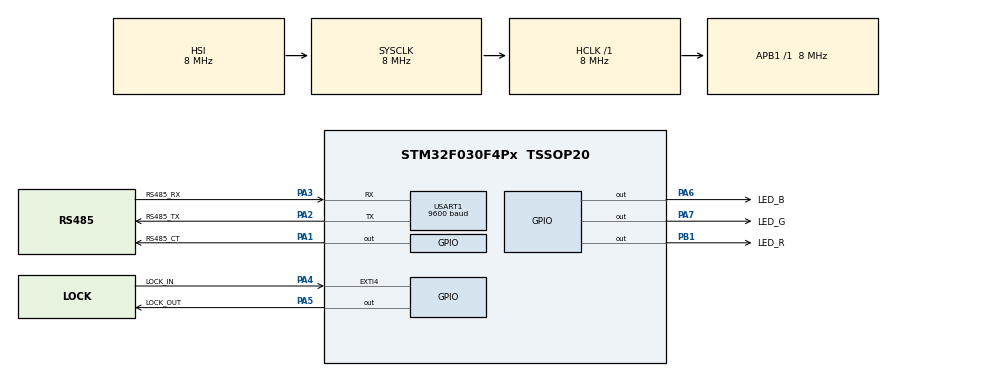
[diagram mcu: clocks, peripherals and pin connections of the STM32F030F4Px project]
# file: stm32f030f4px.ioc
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Dma.Request0=USART1_RX
Dma.Request1=USART1_TX
Dma.USART1_RX.0.Direction=DMA_PERIPH_TO_MEMORY
Dma.USART1_RX.0.Instance=DMA1_Channel3
Dma.USART1_RX.0.MemDataAlignment=DMA_MDATAALIGN_BYTE
Dma.USART1_RX.0.MemInc=DMA_MINC_ENABLE
Dma.USART1_RX.0.Mode=DMA_CIRCULAR
Dma.USART1_RX.0.PeriphDataAlignment=DMA_PDATAALIGN_BYTE
Dma.USART1_RX.0.PeriphInc=DMA_PINC_DISABLE
Dma.USART1_RX.0.Priority=DMA_PRIORITY_LOW
Dma.USART1_TX.1.Direction=DMA_MEMORY_TO_PERIPH
Dma.USART1_TX.1.Instance=DMA1_Channel2
Dma.USART1_TX.1.MemDataAlignment=DMA_MDATAALIGN_BYTE
Dma.USART1_TX.1.MemInc=DMA_MINC_ENABLE
Dma.USART1_TX.1.Mode=DMA_NORMAL
Dma.USART1_TX.1.PeriphDataAlignment=DMA_PDATAALIGN_BYTE
Dma.USART1_TX.1.PeriphInc=DMA_PINC_DISABLE
Dma.USART1_TX.1.Priority=DMA_PRIORITY_LOW
Mcu.Family=STM32F0
Mcu.Name=STM32F030F4Px
Mcu.Package=TSSOP20
NVIC.DMA1_Channel2_3_IRQn=true\:0\:0\:false\:false\:true\:false\:true\:true
NVIC.EXTI4_15_IRQn=true\:0\:0\:false\:false\:true\:true\:true\:true
NVIC.USART1_IRQn=true\:0\:0\:false\:false\:true\:true\:true\:true
PA1.GPIO_Label=RS485_CT
PA1.Signal=GPIO_Output
PA13.Mode=Serial_Wire
PA13.Signal=SYS_SWDIO
PA14.Mode=Serial_Wire
PA14.Signal=SYS_SWCLK
PA2.GPIO_Label=RS485_TX
PA2.Mode=Asynchronous
PA2.Signal=USART1_TX
PA3.GPIO_Label=RS485_RX
PA3.Mode=Asynchronous
PA3.Signal=USART1_RX
PA4.GPIO_Label=LOCK_IN
PA4.GPIO_ModeDefaultEXTI=GPIO_MODE_IT_RISING_FALLING
PA4.Signal=GPXTI4
PA5.GPIO_Label=LOCK_OUT
PA5.Signal=GPIO_Output
PA6.GPIO_Label=LED_B
PA6.Signal=GPIO_Output
PA7.GPIO_Label=LED_G
PA7.Signal=GPIO_Output
PB1.GPIO_Label=LED_R
PB1.Signal=GPIO_Output
PF0-OSC_IN.Mode=HSE-External-Oscillator
PF0-OSC_IN.Signal=RCC_OSC_IN
PF1-OSC_OUT.Mode=HSE-External-Oscillator
PF1-OSC_OUT.Signal=RCC_OSC_OUT
ProjectManager.HeapSize=0x200
ProjectManager.StackSize=0x400
ProjectManager.TargetToolchain=STM32CubeIDE
RCC.AHBFreq_Value=8000000
RCC.APB1Freq_Value=8000000
RCC.APB1TimFreq_Value=8000000
RCC.HCLKFreq_Value=8000000
RCC.PLLMUL=RCC_PLL_MUL6
RCC.PLLSourceVirtual=RCC_PLLSOURCE_HSE
RCC.SYSCLKFreq_VALUE=8000000
USART1.BaudRate=9600
USART1.VirtualMode-Asynchronous=VM_ASYNC
board=custom

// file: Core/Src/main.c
/* USER CODE BEGIN Header */
/**
  ******************************************************************************
  * @file           : main.c
  * @brief          : Main program body
  ******************************************************************************
  * @attention
  *
  * Copyright (c) 2026 STMicroelectronics.
  * All rights reserved.
  *
  * This software is licensed under terms that can be found in the LICENSE file
  * in the root directory of this software component.
  * If no LICENSE file comes with this software, it is provided AS-IS.
  *
  ******************************************************************************
  */
/* USER CODE END Header */
#include "main.h"
#include "dma.h"
#include "usart.h"
#include "gpio.h"

/* USER CODE BEGIN Includes */
#include "drv_mcu.h"
#include "app_doorlock.h"
/* USER CODE END Includes */

void SystemClock_Config(void);

int main(void)
{

  /* MCU Configuration--------------------------------------------------------*/

  /* Reset of all peripherals, Initializes the Flash interface and the Systick. */
  HAL_Init();

  /* Configure the system clock */
  SystemClock_Config();

  /* Initialize all configured peripherals */
  MX_GPIO_Init();
  MX_DMA_Init();
  MX_USART1_UART_Init();
  /* USER CODE BEGIN 2 */

  // 1. Init Drivers
  Drv_Init(&huart1);
  __HAL_UART_ENABLE_IT(&huart1, UART_IT_IDLE); // Interrupt Idle tetap dibutuhkan

  // 2. Init Application
  App_Init();

  /* USER CODE END 2 */

  /* Infinite loop */
  /* USER CODE BEGIN WHILE */
  while (1)
  {
	  // 3. Process Application Logic
	  App_Process();
    /* USER CODE END WHILE */

  }
}

void SystemClock_Config(void)
{
  RCC_OscInitTypeDef RCC_OscInitStruct = {0};
  RCC_ClkInitTypeDef RCC_ClkInitStruct = {0};
  RCC_PeriphCLKInitTypeDef PeriphClkInit = {0};

  /** Initializes the RCC Oscillators according to the specified parameters
  * in the RCC_OscInitTypeDef structure.
  */
  RCC_OscInitStruct.OscillatorType = RCC_OSCILLATORTYPE_HSI;
  RCC_OscInitStruct.HSIState = RCC_HSI_ON;
  RCC_OscInitStruct.HSICalibrationValue = RCC_HSICALIBRATION_DEFAULT;
  RCC_OscInitStruct.PLL.PLLState = RCC_PLL_NONE;
  if (HAL_RCC_OscConfig(&RCC_OscInitStruct) != HAL_OK)
  {
    Error_Handler();
  }

  /** Initializes the CPU, AHB and APB buses clocks
  */
  RCC_ClkInitStruct.ClockType = RCC_CLOCKTYPE_HCLK|RCC_CLOCKTYPE_SYSCLK
                              |RCC_CLOCKTYPE_PCLK1;
  RCC_ClkInitStruct.SYSCLKSource = RCC_SYSCLKSOURCE_HSI;
  RCC_ClkInitStruct.AHBCLKDivider = RCC_SYSCLK_DIV1;
  RCC_ClkInitStruct.APB1CLKDivider = RCC_HCLK_DIV1;

  if (HAL_RCC_ClockConfig(&RCC_ClkInitStruct, FLASH_LATENCY_0) != HAL_OK)
  {
    Error_Handler();
  }
  PeriphClkInit.PeriphClockSelection = RCC_PERIPHCLK_USART1;
  PeriphClkInit.Usart1ClockSelection = RCC_USART1CLKSOURCE_PCLK1;
  if (HAL_RCCEx_PeriphCLKConfig(&PeriphClkInit) != HAL_OK)
  {
    Error_Handler();
  }
}

/* USER CODE BEGIN 4 */
// Callback Exti dipindahkan pemanggilannya ke App Layer
void HAL_GPIO_EXTI_Callback(uint16_t GPIO_Pin)
{
    if (GPIO_Pin == LOCK_IN_Pin) {
        App_SignalLockTrigger();
    }
}
/* USER CODE END 4 */

void Error_Handler(void)
{
  __disable_irq();
  while (1)
  {
  }
}
